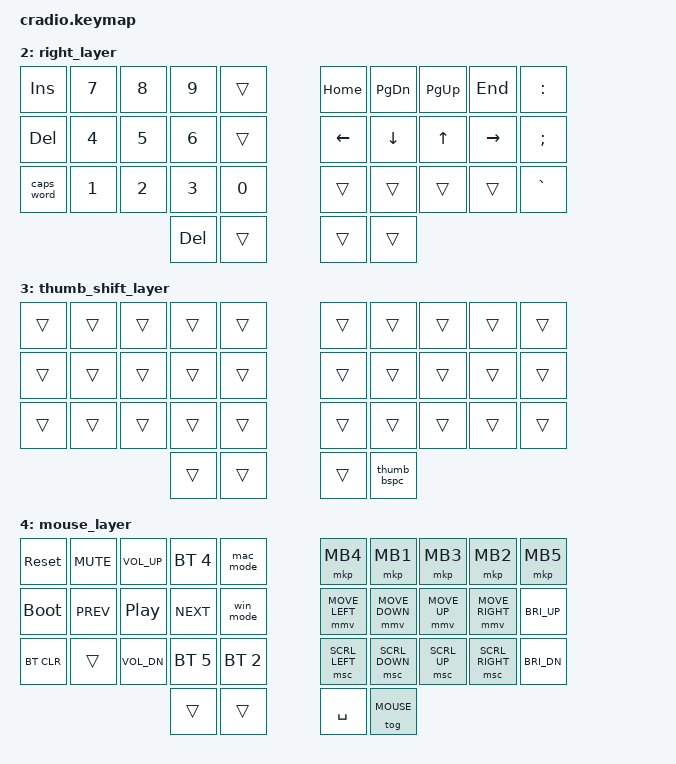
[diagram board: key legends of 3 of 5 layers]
// Copyright (c) 2022 The ZMK Contributors
// SPDX-License-Identifier: MIT

#include <behaviors.dtsi>
#include <dt-bindings/zmk/keys.h>
#include <dt-bindings/zmk/bt.h>

#define MAC 0
#define WIN 1
#define NAV 2
#define THUMB_SHIFT 3
#define MOUSE 4

// Home-row modifiers accept opposite-hand keys and all four thumbs.
#define HRML(k1,k2,k3,k4) &hml LSHFT k1  &hml LALT k2  &hml LCTRL k3  &hml LGUI k4
#define HRMR(k1,k2,k3,k4) &hmr RGUI k1  &hmr RCTRL k2  &hmr RALT k3  &hmr RSHFT k4

// Mouse emulation related stuff
#define ZMK_POINTING_DEFAULT_MOVE_VAL 1200  // default: 600
#define ZMK_POINTING_DEFAULT_SCRL_VAL 20    // default: 10
#include <dt-bindings/zmk/pointing.h>

/ {
    behaviors {
        hml: home_row_left {
            compatible = "zmk,behavior-hold-tap";
            #binding-cells = <2>;
            flavor = "balanced";
            tapping-term-ms = <280>;
            quick-tap-ms = <175>;
            require-prior-idle-ms = <150>;
            hold-trigger-key-positions = <5 6 7 8 9 15 16 17 18 19 25 26 27 28 29 30 31 32 33>;
            hold-trigger-on-release;
            bindings = <&kp>, <&kp>;
        };
        hmr: home_row_right {
            compatible = "zmk,behavior-hold-tap";
            #binding-cells = <2>;
            flavor = "balanced";
            tapping-term-ms = <280>;
            quick-tap-ms = <175>;
            require-prior-idle-ms = <150>;
            hold-trigger-key-positions = <0 1 2 3 4 10 11 12 13 14 20 21 22 23 24 30 31 32 33>;
            hold-trigger-on-release;
            bindings = <&kp>, <&kp>;
        };
        thumb_mod: thumb_modifier {
            compatible = "zmk,behavior-hold-tap";
            #binding-cells = <2>;
            flavor = "balanced";
            tapping-term-ms = <200>;
            bindings = <&kp>, <&kp>;
        };
        tab_shift: tab_thumb_shift {
            compatible = "zmk,behavior-hold-tap";
            #binding-cells = <2>;
            flavor = "balanced";
            tapping-term-ms = <200>;
            bindings = <&thumb_shift>, <&kp>;
        };
        esc_nav: escape_navigation {
            compatible = "zmk,behavior-hold-tap";
            #binding-cells = <2>;
            flavor = "balanced";
            tapping-term-ms = <200>;
            bindings = <&mo>, <&kp>;
        };
        // Mask only the Shift supplied by the thumb; retain Ctrl/Alt/GUI.
        thumb_bspc: thumb_backspace {
            compatible = "zmk,behavior-mod-morph";
            #binding-cells = <0>;
            bindings = <&kp BSPC>, <&kp BSPC>;
            mods = <(MOD_LSFT)>;
        };
    };

    macros {
        // The layer changes only the opposite thumb to repeating Backspace.
        thumb_shift: thumb_shift {
            compatible = "zmk,behavior-macro";
            #binding-cells = <0>;
            wait-ms = <0>;
            tap-ms = <0>;
            bindings = <&macro_press &mo THUMB_SHIFT &kp LSHFT>,
                       <&macro_pause_for_release>,
                       <&macro_release &kp LSHFT &mo THUMB_SHIFT>;
        };
        mac_mode: mac_mode {
            compatible = "zmk,behavior-macro";
            #binding-cells = <0>;
            bindings = <&to MAC &bt BT_SEL 0>;
        };
        win_mode: win_mode {
            compatible = "zmk,behavior-macro";
            #binding-cells = <0>;
            bindings = <&to WIN &bt BT_SEL 1>;
        };
    };

    combos {
        compatible = "zmk,combos";
        combo_lbkt {
            layers = <MAC WIN THUMB_SHIFT>;
            timeout-ms = <50>;
            key-positions = <3 4>;
            bindings = <&kp LBKT>;
        };
        combo_rbkt {
            layers = <MAC WIN THUMB_SHIFT>;
            timeout-ms = <50>;
            key-positions = <5 6>;
            bindings = <&kp RBKT>;
        };
        combo_lpar {
            layers = <MAC WIN THUMB_SHIFT>;
            timeout-ms = <50>;
            key-positions = <13 14>;
            bindings = <&kp LPAR>;
        };
        combo_rpar {
            layers = <MAC WIN THUMB_SHIFT>;
            timeout-ms = <50>;
            key-positions = <15 16>;
            bindings = <&kp RPAR>;
        };
        combo_lbrc {
            layers = <MAC WIN THUMB_SHIFT>;
            timeout-ms = <50>;
            key-positions = <23 24>;
            bindings = <&kp LBRC>;
        };
        combo_rbrc {
            layers = <MAC WIN THUMB_SHIFT>;
            timeout-ms = <50>;
            key-positions = <25 26>;
            bindings = <&kp RBRC>;
        };
        combo_excl {
            layers = <MAC WIN THUMB_SHIFT>;
            timeout-ms = <50>;
            key-positions = <0 10>;
            bindings = <&kp EXCL>;
        };
        combo_at {
            layers = <MAC WIN THUMB_SHIFT>;
            timeout-ms = <50>;
            key-positions = <1 11>;
            bindings = <&kp AT>;
        };
        combo_hash {
            layers = <MAC WIN THUMB_SHIFT>;
            timeout-ms = <50>;
            key-positions = <2 12>;
            bindings = <&kp HASH>;
        };
        combo_dllr {
            layers = <MAC WIN THUMB_SHIFT>;
            timeout-ms = <50>;
            key-positions = <3 13>;
            bindings = <&kp DLLR>;
        };
        combo_prcnt {
            layers = <MAC WIN THUMB_SHIFT>;
            timeout-ms = <50>;
            key-positions = <4 14>;
            bindings = <&kp PRCNT>;
        };
        combo_caret {
            layers = <MAC WIN THUMB_SHIFT>;
            timeout-ms = <50>;
            key-positions = <5 15>;
            bindings = <&kp CARET>;
        };
        combo_amps {
            layers = <MAC WIN THUMB_SHIFT>;
            timeout-ms = <50>;
            key-positions = <6 16>;
            bindings = <&kp AMPS>;
        };
        combo_astrk {
            layers = <MAC WIN THUMB_SHIFT>;
            timeout-ms = <50>;
            key-positions = <7 17>;
            bindings = <&kp ASTRK>;
        };
        combo_minus {
            layers = <MAC WIN THUMB_SHIFT>;
            timeout-ms = <50>;
            key-positions = <15 25>;
            bindings = <&kp MINUS>;
        };
        combo_under {
            layers = <MAC WIN THUMB_SHIFT>;
            timeout-ms = <50>;
            key-positions = <16 26>;
            bindings = <&kp UNDER>;
        };
        combo_equal {
            layers = <MAC WIN THUMB_SHIFT>;
            timeout-ms = <50>;
            key-positions = <17 27>;
            bindings = <&kp EQUAL>;
        };
        combo_plus {
            layers = <MAC WIN THUMB_SHIFT>;
            timeout-ms = <50>;
            key-positions = <8 18>;
            bindings = <&kp PLUS>;
        };
        combo_bslh {
            layers = <MAC WIN THUMB_SHIFT>;
            timeout-ms = <50>;
            key-positions = <28 29>;
            bindings = <&kp BSLH>;
        };
        combo_pipe {
            layers = <MAC WIN THUMB_SHIFT>;
            timeout-ms = <50>;
            key-positions = <18 28>;
            bindings = <&kp PIPE>;
        };
        combo_tilde {
            layers = <MAC WIN THUMB_SHIFT>;
            timeout-ms = <50>;
            key-positions = <11 21>;
            bindings = <&kp TILDE>;
        };
        combo_colon {
            layers = <MAC WIN THUMB_SHIFT>;
            timeout-ms = <50>;
            key-positions = <9 19>;
            bindings = <&kp COLON>;
        };
        combo_semi {
            layers = <MAC WIN THUMB_SHIFT>;
            timeout-ms = <50>;
            key-positions = <19 29>;
            bindings = <&kp SEMI>;
        };
        combo_grave {
            layers = <MAC WIN THUMB_SHIFT>;
            timeout-ms = <50>;
            key-positions = <10 20>;
            bindings = <&kp GRAVE>;
        };
        combo_mouse {
            layers = <MAC WIN THUMB_SHIFT MOUSE>;
            timeout-ms = <50>;
            key-positions = <32 33>;
            bindings = <&tog MOUSE>;
        };
    };

    keymap {
        compatible = "zmk,keymap";
        default_layer {
            bindings = <
        //╭──────────┬──────────┬──────────┬──────────┬──────────╮   ╭──────────┬──────────┬──────────┬──────────┬──────────╮
        //│  Q       │  W       │  E       │  R       │  T       │   │  Y       │  U       │  I       │  O       │  P       │
            &kp Q      &kp W      &kp E      &kp R      &kp T          &kp Y      &kp U      &kp I      &kp O      &kp P
        //├──────────┼──────────┼──────────┼──────────┼──────────┤   ├──────────┼──────────┼──────────┼──────────┼──────────┤
        //│  A       │  S       │  D       │  F       │  G       │   │  H       │  J       │  K       │  L       │ ' "      │
            HRML(A,        S,         D,         F)     &kp G          &kp H      HRMR(J,        K,         L,        SQT)
        //├──────────┼──────────┼──────────┼──────────┼──────────┤   ├──────────┼──────────┼──────────┼──────────┼──────────┤
        //│  Z       │  X       │  C       │  V       │  B       │   │  N       │  M       │ , <      │ . >      │ / ?      │
            &kp Z      &kp X      &kp C      &kp V      &kp B          &kp N      &kp M      &kp COMMA  &kp DOT    &kp FSLH
        //╰──────────┴──────────┴──────────┼──────────┼──────────┤   ├──────────┼──────────┼──────────┴──────────┴──────────╯
                                            &tab_shift 0 TAB &thumb_mod LGUI ENTER &kp SPACE &esc_nav NAV ESC
        //                                 ╰──────────┴──────────╯   ╰──────────┴──────────╯
            >;
        };

        windows_layer {
            bindings = <
        //╭──────────┬──────────┬──────────┬──────────┬──────────╮   ╭──────────┬──────────┬──────────┬──────────┬──────────╮
        //│  Q       │  W       │  E       │  R       │  T       │   │  Y       │  U       │  I       │  O       │  P       │
            &kp Q      &kp W      &kp E      &kp R      &kp T          &kp Y      &kp U      &kp I      &kp O      &kp P
        //├──────────┼──────────┼──────────┼──────────┼──────────┤   ├──────────┼──────────┼──────────┼──────────┼──────────┤
        //│  A       │  S       │  D       │  F       │  G       │   │  H       │  J       │  K       │  L       │ ' "      │
            HRML(A,        S,         D,         F)     &kp G          &kp H      HRMR(J,        K,         L,        SQT)
        //├──────────┼──────────┼──────────┼──────────┼──────────┤   ├──────────┼──────────┼──────────┼──────────┼──────────┤
        //│  Z       │  X       │  C       │  V       │  B       │   │  N       │  M       │ , <      │ . >      │ / ?      │
            &kp Z      &kp X      &kp C      &kp V      &kp B          &kp N      &kp M      &kp COMMA  &kp DOT    &kp FSLH
        //╰──────────┴──────────┴──────────┼──────────┼──────────┤   ├──────────┼──────────┼──────────┴──────────┴──────────╯
                                            &tab_shift 0 TAB &thumb_mod LCTRL ENTER &kp SPACE &esc_nav NAV ESC
        //                                 ╰──────────┴──────────╯   ╰──────────┴──────────╯
            >;
        };

        right_layer {
            bindings = <
        //╭──────────┬──────────┬──────────┬──────────┬──────────╮   ╭──────────┬──────────┬──────────┬──────────┬──────────╮
        //│ INSERT   │  7       │  8       │  9       │          │   │ HOME     │ PAGE DN  │ PAGE UP  │ END      │  :       │
            &kp INS    &kp N7     &kp N8     &kp N9     &trans         &kp HOME   &kp PG_DN  &kp PG_UP  &kp END    &kp COLON
        //├──────────┼──────────┼──────────┼──────────┼──────────┤   ├──────────┼──────────┼──────────┼──────────┼──────────┤
        //│ DELETE   │  4       │  5       │  6       │          │   │ LEFT     │ DOWN     │ UP       │ RIGHT    │  ;       │
            &kp DEL    &kp N4     &kp N5     &kp N6     &trans         &kp LEFT   &kp DOWN   &kp UP   &kp RIGHT   &kp SEMI
        //├──────────┼──────────┼──────────┼──────────┼──────────┤   ├──────────┼──────────┼──────────┼──────────┼──────────┤
        //│ CAPS     │  1       │  2       │  3       │  0       │   │          │          │          │          │  `       │
           &caps_word  &kp N1     &kp N2     &kp N3     &kp N0         &trans     &trans     &trans     &trans     &kp GRAVE
        //╰──────────┴──────────┴──────────┼──────────┼──────────┤   ├──────────┼──────────┼──────────┴──────────┴──────────╯
                                             &kp DEL    &trans         &trans     &trans
        //                                 ╰──────────┴──────────╯   ╰──────────┴──────────╯
            >;
        };

        // Active only while the left Tab/Shift thumb is held.
        // Other Shift keys do not turn Escape into Backspace.
        thumb_shift_layer {
            bindings = <
                &trans &trans &trans &trans &trans   &trans &trans &trans &trans &trans
                &trans &trans &trans &trans &trans   &trans &trans &trans &trans &trans
                &trans &trans &trans &trans &trans   &trans &trans &trans &trans &trans
                                     &trans &trans   &trans &thumb_bspc
            >;
        };

        mouse_layer {
            bindings = <
        //╭──────────┬──────────┬──────────┬──────────┬──────────╮   ╭──────────┬──────────┬──────────┬──────────┬──────────╮
        //│ RESET    │ MUTE     │ VOL UP   │PROFILE 4 │ MAC MODE │   │ Mouse BB │ Mouse LB │ Mouse MB │ Mouse RB │ Mouse FB │
           &sys_reset &kp C_MUTE &kp C_VOL_UP &bt BT_SEL 4 &mac_mode      &mkp MB4   &mkp MB1   &mkp MB3   &mkp MB2   &mkp MB5
        //├──────────┼──────────┼──────────┼──────────┼──────────┤   ├──────────┼──────────┼──────────┼──────────┼──────────┤
        //│BOOTLOADER│ PREV     │ PLAY     │ NEXT     │ WIN MODE │   │ Mouse mvL│ Mouse mvD│ Mouse mvU│ Mouse mvR│ Bright UP│
          &bootloader &kp C_PREV  &kp C_PP  &kp C_NEXT   &win_mode    &mmv MOVE_LEFT &mmv MOVE_DOWN &mmv MOVE_UP &mmv MOVE_RIGHT &kp C_BRI_UP
        //├──────────┼──────────┼──────────┼──────────┼──────────┤   ├──────────┼──────────┼──────────┼──────────┼──────────┤
        //│ CLEAR BT │          │ VOL DOWN │PROFILE 5 │PROFILE 2 │   │ Mouse scL│ Mouse scD│ Mouse scU│ Mouse scR│ Br DOWN  │
           &bt BT_CLR &trans &kp C_VOL_DN   &bt BT_SEL 5 &bt BT_SEL 2 &msc SCRL_LEFT &msc SCRL_DOWN &msc SCRL_UP &msc SCRL_RIGHT &kp C_BRI_DN
        //╰──────────┴──────────┴──────────┼──────────┼──────────┤   ├──────────┼──────────┼──────────┴──────────┴──────────╯
                                             &trans     &trans         &kp SPACE  &tog MOUSE
        //                                 ╰──────────┴──────────╯   ╰──────────┴──────────╯
            >;
        };

    };
};
